AUTOSAR XML (schema 00049)
package /ComponentTypes
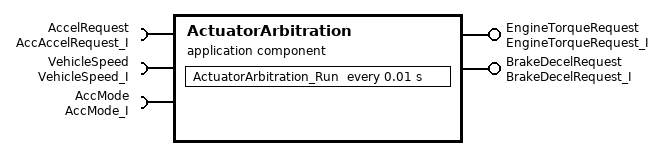
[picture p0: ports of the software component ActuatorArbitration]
  application sw component type ActuatorArbitration
    require port AccelRequest: nonqueued-receiver-com-spec{data-element=AccelRequest, alive-timeout=0.06, handle-never-received=true, init-value=constant-reference=LongitudinalAccel_IV}, required-interface=AccAccelRequest_I
    require port VehicleSpeed: nonqueued-receiver-com-spec{data-element=VehicleSpeed, init-value=constant-reference=VehicleSpeed_IV}, required-interface=VehicleSpeed_I
    require port AccMode: mode-switch-receiver-com-spec{enhanced-mode-api=false, mode-group=accMode, supports-asynchronous-mode-switch=false}, required-interface=AccMode_I
    provide port EngineTorqueRequest: nonqueued-sender-com-spec{data-element=TorqueRequest, init-value=constant-reference=TorqueRequest_IV}, provided-interface=EngineTorqueRequest_I
    provide port BrakeDecelRequest: nonqueued-sender-com-spec{data-element=DecelRequest, init-value=constant-reference=LongitudinalAccel_IV}, provided-interface=BrakeDecelRequest_I
    behavior ActuatorArbitration_InternalBehavior: data-type-mapping=AccTypeMappingSet
      init event IT_ActuatorArbitration_Init: start-on-event=ActuatorArbitration_Init
      timing event TMT_ActuatorArbitration_Run: start-on-event=ActuatorArbitration_Run, period=0.01
      data received event DRT_ActuatorArbitration_OnAccelRequest_AccelRequest_AccelRequest: start-on-event=ActuatorArbitration_OnAccelRequest, data=AccelRequest.AccelRequest
      swc mode switch event MST_ActuatorArbitration_OnAccActivated: start-on-event=ActuatorArbitration_OnAccActivated, activation=ON-ENTRY, mode=AccMode.accMode.ACTIVE
      port-api-options:
        enable-take-address=false, indirect-api=false, port=AccelRequest
        enable-take-address=false, indirect-api=false, port=AccMode
        enable-take-address=false, indirect-api=false, port=BrakeDecelRequest
        enable-take-address=false, indirect-api=false, port=EngineTorqueRequest
        enable-take-address=false, indirect-api=false, port=VehicleSpeed
      4 x runnable:
        ActuatorArbitration_Init
        ActuatorArbitration_Run
          data-receive-point-by-arguments:
            access REC_AccelRequest_AccelRequest: accessed-variable=AccelRequest.AccelRequest
            access REC_VehicleSpeed_VehicleSpeed: accessed-variable=VehicleSpeed.VehicleSpeed
          data-send-points:
            access SEND_EngineTorqueRequest_TorqueRequest: accessed-variable=EngineTorqueRequest.TorqueRequest
            access SEND_BrakeDecelRequest_DecelRequest: accessed-variable=BrakeDecelRequest.DecelRequest
        ActuatorArbitration_OnAccelRequest
          data-receive-point-by-arguments:
            access REC_AccelRequest_AccelRequest: accessed-variable=AccelRequest.AccelRequest
        ActuatorArbitration_OnAccActivated
  swc implementation ActuatorArbitration_Implementation: behavior=ActuatorArbitration_InternalBehavior
